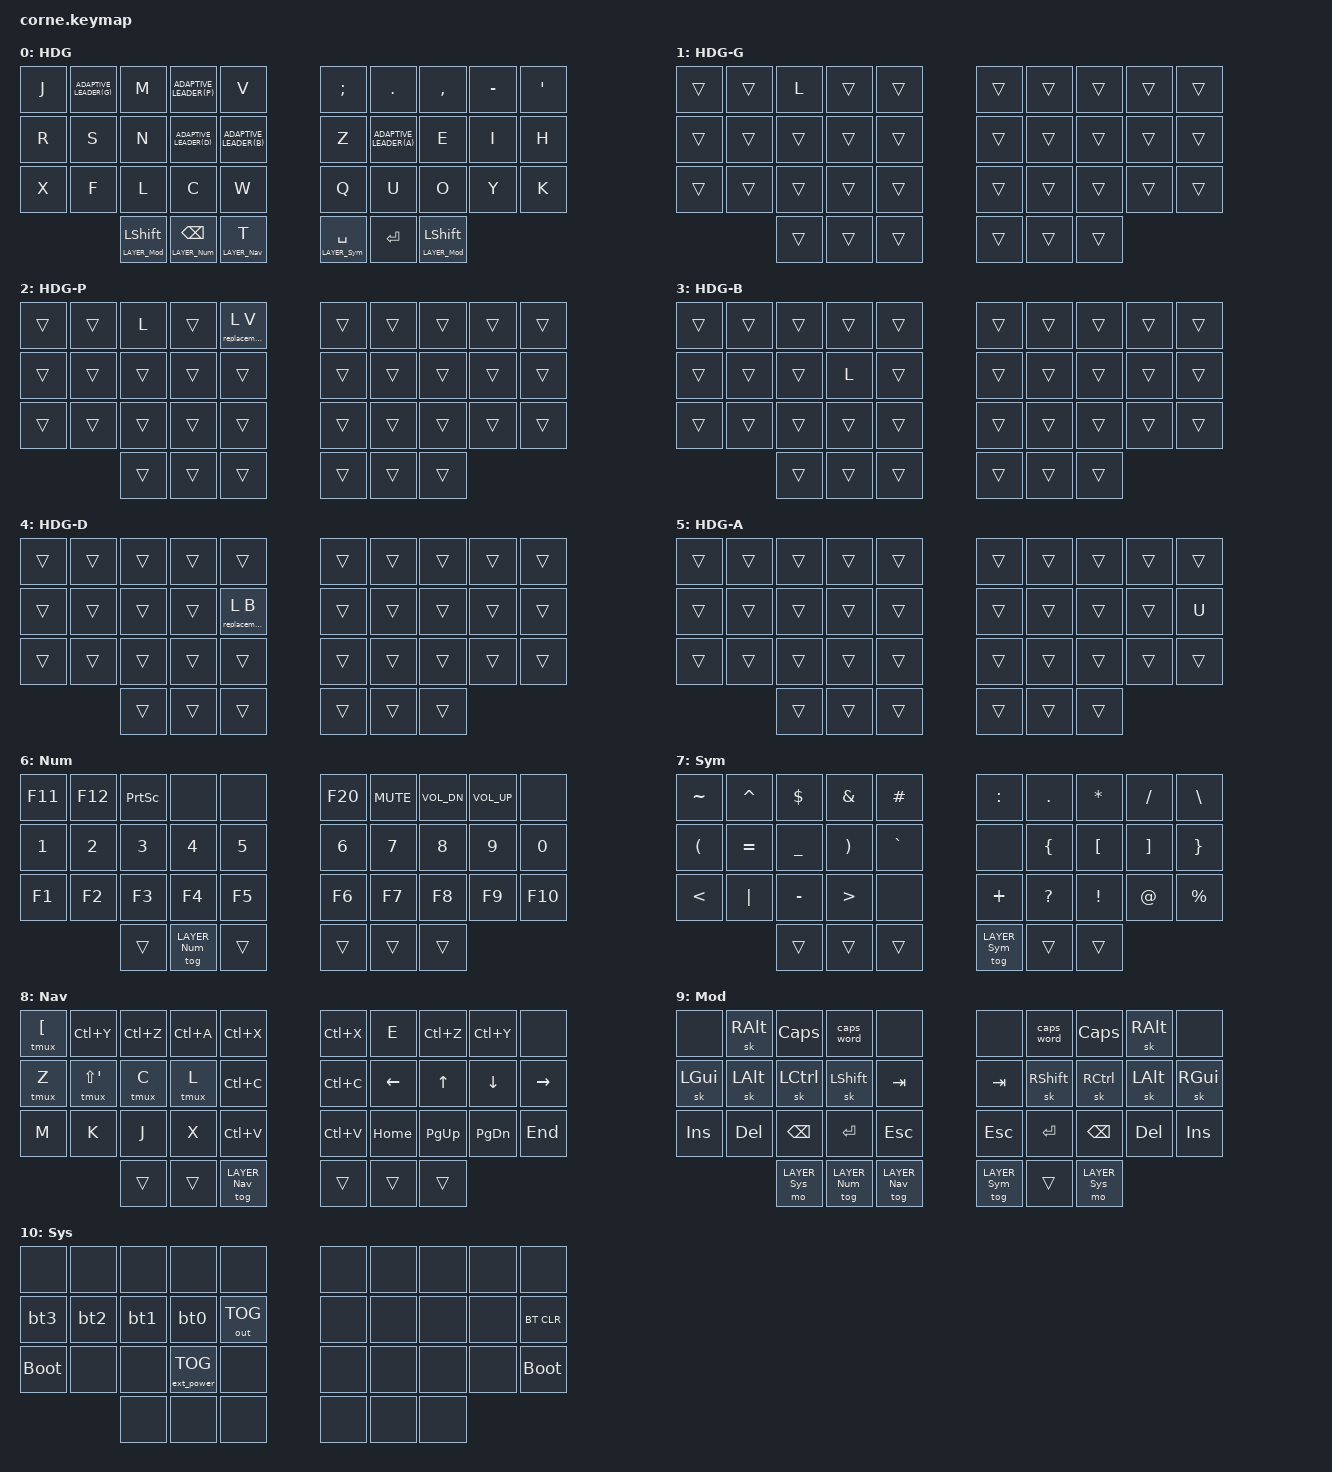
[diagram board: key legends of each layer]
#include <behaviors.dtsi>
#include <dt-bindings/zmk/bt.h>
#include <dt-bindings/zmk/ext_power.h>
#include <dt-bindings/zmk/keys.h>
#include <dt-bindings/zmk/outputs.h>

#define LAYER_HandsDownGold 0
#define LAYER_HdgAdaptiveAfterG 1
#define LAYER_HdgAdaptiveAfterP 2
#define LAYER_HdgAdaptiveAfterB 3
#define LAYER_HdgAdaptiveAfterD 4
#define LAYER_HdgAdaptiveAfterA 5
#define LAYER_Num 6
#define LAYER_Sym 7
#define LAYER_Nav 8
#define LAYER_Mod 9
#define LAYER_Sys 10

#define ADAPTIVE_LEADER(key) &adaptive_leader key LAYER_HdgAdaptiveAfter##key

#define BT_TAP_DANCE(name, btnum) name: name { \
    compatible = "zmk,behavior-tap-dance"; \
    #binding-cells = <0>; \
    tapping-term-ms = <200>; \
    bindings = <&bt BT_SEL btnum>, <&bt BT_DISC btnum>; \
}

&lt {
    tapping-term-ms = <200>;
    quick-tap-ms = <200>;
};

/ {
chosen {
    zmk,physical-layout = &foostan_corne_5col_layout;
};

behaviors {
    adaptive_layer: adaptive_layer {
        compatible = "zmk,behavior-sticky-key";
        #binding-cells = <1>;
        bindings = <&mo>;
        release-after-ms = <200>;
        quick-release;
    };  

    behavior_caps_word {
        continue-list = <
            UNDERSCORE MINUS BACKSPACE DELETE
            N1 N2 N3 N4 N5 N6 N7 N8 N9 N0
        >;
    };

    BT_TAP_DANCE(bt0, 0);
    BT_TAP_DANCE(bt1, 1);
    BT_TAP_DANCE(bt2, 2);
    BT_TAP_DANCE(bt3, 3);

    mo_sk: mo_sk {
        compatible = "zmk,behavior-hold-tap";
        #binding-cells = <2>;
        tapping-term-ms = <200>;
        quick-tap-ms = <200>;
        bindings = <&mo>, <&sk>;
    };
};

macros {
    tmux: tmux {
            compatible = "zmk,behavior-macro-one-param";
            #binding-cells = <1>;
            bindings = <&macro_tap>
                , <&kp LC(A)>
                , <&macro_param_1to1>
                , <&kp MACRO_PLACEHOLDER>;
    };
    
    // Taps key and activates a layer
    adaptive_leader: adaptive_leader {
        compatible = "zmk,behavior-macro-two-param";
        #binding-cells = <2>;
        tap-ms = <0>;
        wait-ms = <0>;
        bindings = <&macro_press>
            , <&macro_param_1to1>
            , <&kp MACRO_PLACEHOLDER>
            , <&macro_param_2to1>
            , <&adaptive_layer MACRO_PLACEHOLDER>
            , <&macro_pause_for_release>
            , <&macro_release>
            , <&macro_param_1to1>
            , <&kp MACRO_PLACEHOLDER>
            , <&macro_param_2to1>
            , <&adaptive_layer MACRO_PLACEHOLDER>;
    };
    
    replacement_adaptive: replacement_adaptive {
        compatible = "zmk,behavior-macro-two-param";
        #binding-cells = <2>;
        tap-ms = <0>;
        wait-ms = <0>;
        bindings = <&kp Z>
            , <&kp BSPC>
            , <&kp BSPC>
            , <&macro_param_1to1>
            , <&kp MACRO_PLACEHOLDER>
            , <&macro_press>
            , <&macro_param_2to1>
            , <&kp MACRO_PLACEHOLDER>
            , <&macro_pause_for_release>
            , <&macro_release>
            , <&macro_param_2to1>
            , <&kp MACRO_PLACEHOLDER>;
    };
};

keymap {
    compatible = "zmk,keymap";

    HandsDownGold {
        display-name = "HDG";
        bindings = <
&kp J ADAPTIVE_LEADER(G) &kp M                   ADAPTIVE_LEADER(P) &kp V                       &kp SEMI              &kp DOT              &kp COMMA &kp MINUS &kp SQT
&kp R &kp S              &kp N                   ADAPTIVE_LEADER(D) ADAPTIVE_LEADER(B)          &kp Z                 ADAPTIVE_LEADER(A)   &kp E     &kp I     &kp H
&kp X &kp F              &kp L                   &kp C              &kp W                       &kp Q                 &kp U                &kp O     &kp Y     &kp K
                         &mo_sk LAYER_Mod LSHIFT &lt LAYER_Num BSPC &lt LAYER_Nav T             &lt LAYER_Sym SPACE   &kp ENTER            &mo_sk LAYER_Mod LSHIFT
        >;
    };

    HdgAdaptiveAfterG {
		display-name = "HDG-G";
		bindings = <
&trans &trans &kp L  &trans &trans      &trans &trans &trans &trans &trans
&trans &trans &trans &trans &trans      &trans &trans &trans &trans &trans
&trans &trans &trans &trans &trans	&trans &trans &trans &trans &trans
              &trans &trans &trans	&trans &trans &trans
        >;
    };

    HdgAdaptiveAfterP {
		display-name = "HDG-P";
		bindings = <
&trans &trans &kp L  &trans &replacement_adaptive L V       &trans &trans &trans &trans &trans
&trans &trans &trans &trans &trans                          &trans &trans &trans &trans &trans
&trans &trans &trans &trans &trans	                    &trans &trans &trans &trans &trans
              &trans &trans &trans		            &trans &trans &trans
        >;
    };

    HdgAdaptiveAfterB {
		display-name = "HDG-B";
		bindings = <
&trans &trans &trans &trans &trans                          &trans &trans &trans &trans &trans
&trans &trans &trans &kp L  &trans                          &trans &trans &trans &trans &trans
&trans &trans &trans &trans &trans	                    &trans &trans &trans &trans &trans
              &trans &trans &trans	                    &trans &trans &trans
        >;
    };

    HdgAdaptiveAfterD {
		display-name = "HDG-D";
		bindings = <
&trans &trans &trans &trans &trans                          &trans &trans &trans &trans &trans
&trans &trans &trans &trans &replacement_adaptive L B       &trans &trans &trans &trans &trans
&trans &trans &trans &trans &trans	                    &trans &trans &trans &trans &trans
              &trans &trans &trans		            &trans &trans &trans
        >;
    };

    HdgAdaptiveAfterA {
		display-name = "HDG-A";
		bindings = <
&trans &trans &trans &trans &trans                          &trans &trans &trans &trans &trans
&trans &trans &trans &trans &trans                          &trans &trans &trans &trans &kp U
&trans &trans &trans &trans &trans	                    &trans &trans &trans &trans &trans
              &trans &trans &trans		            &trans &trans &trans
        >;
    };

    Num {
        display-name = "Num";
        bindings = <
&kp F11 &kp F12 &kp PSCRN &none &none                      &kp F20 &kp C_MUTE &kp C_VOL_DN &kp C_VOL_UP &none
&kp N1  &kp N2  &kp N3    &kp N4           &kp N5          &kp N6  &kp N7     &kp N8       &kp N9       &kp N0
&kp F1  &kp F2  &kp F3    &kp F4           &kp F5          &kp F6  &kp F7     &kp F8       &kp F9       &kp F10
                &trans    &tog LAYER_Num   &trans          &trans  &trans     &trans 
        >;
    };

    Sym {
        display-name = "Sym";
        bindings = <
&kp TILDE &kp CARET &kp DLLR  &kp AMPS &kp HASH        &kp COLON      &kp DOT    &kp STAR &kp FSLH &kp BSLH
&kp LPAR  &kp EQUAL &kp UNDER &kp RPAR &kp GRAVE       &none          &kp LBRC   &kp LBKT &kp RBKT &kp RBRC
&kp LT    &kp PIPE  &kp MINUS &kp GT   &none           &kp PLUS       &kp QMARK  &kp EXCL &kp AT   &kp PRCNT
                    &trans    &trans   &trans          &tog LAYER_Sym &trans &trans 
            >;
        };

    Nav {
        display-name = "Nav";
        bindings = <
&tmux LBKT  &kp LC(Y)     &kp LC(Z) &kp LC(A) &kp LC(X)           &kp LC(X)  &kp E    &kp LC(Z) &kp LC(Y) &none
&tmux Z     &tmux LS(SQT) &tmux C   &tmux L   &kp LC(C)           &kp LC(C)  &kp LEFT &kp UP    &kp DOWN  &kp RIGHT
&kp M       &kp K         &kp J     &kp X     &kp LC(V)           &kp LC(V)  &kp HOME &kp PG_UP &kp PG_DN &kp END
                          &trans    &trans    &tog LAYER_Nav      &trans     &trans   &trans
            >;
        };

    Mod {
        display-name = "Mod";    
        bindings = <
&none    &sk RALT  &kp CAPS      &caps_word &none                  &none          &caps_word  &kp CAPS  &sk RALT &none
&sk LGUI &sk LALT &sk LCTRL      &sk LSHFT  &kp TAB                &kp TAB        &sk RSHFT   &sk RCTRL &sk LALT &sk RGUI
&kp INS  &kp DEL  &kp BSPC       &kp RET    &kp ESC                &kp ESC        &kp RET     &kp BSPC  &kp DEL  &kp INS
                  &mo LAYER_Sys &tog LAYER_Num &tog LAYER_Nav      &tog LAYER_Sym &trans      &mo LAYER_Sys
        >;
    };

    Sys {
        display-name = "Sys";
        bindings = <
            &none &none &none &none &none                    &none &none &none &none &none
            &bt3 &bt2 &bt1 &bt0 &out OUT_TOG                 &none &none &none &none &bt BT_CLR
            &bootloader &none &none &ext_power EP_TOG &none  &none &none &none &none &bootloader
                              &none &none &none              &none &none &none
        >;
    };
};
};  // /
